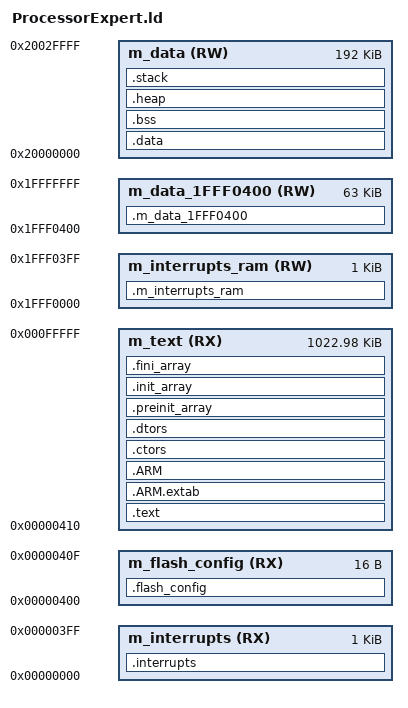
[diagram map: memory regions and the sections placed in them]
/*## ####################################################################### */
/*##                                                                         */
/*##     THIS COMPONENT MODULE IS GENERATED BY THE PROCESSOR EXPERT. DO NOT MODIFY IT. */
/*##                                                                         */
/*##     Filename  : ProcessorExpert.ld                                      */
/*##                                                                         */
/*##     Project   : FRDM-K64F_SDK_FreeRTOS_PEx                              */
/*##                                                                         */
/*##     Processor : MK64FN1M0VLQ12                                          */
/*##                                                                         */
/*##     Compiler  : GNU C Compiler                                          */
/*##                                                                         */
/*##     Date/Time : 2014-10-20, 20:41, # CodeGen: 0                         */
/*##                                                                         */
/*##     Abstract  :                                                         */
/*##                                                                         */
/*##     This file is used by the linker. It describes files to be linked,   */
/*##     memory ranges, stack size, etc. For detailed description about      */
/*##     linker command files see compiler documentation. This file is generated by default. */
/*##     You can switch off generation by setting the property "Generate linker file = no" */
/*##     in the "Build options" tab of the CPU component and then modify this file as needed. */
/*##                                                                         */
/*##                                                                         */
/*## ####################################################################### */
/* Entry Point */
ENTRY(Reset_Handler)

HEAP_SIZE  = DEFINED(__heap_size__)  ? __heap_size__  : 0x0400;
STACK_SIZE = DEFINED(__stack_size__) ? __stack_size__ : 0x0400;
M_VECTOR_RAM_SIZE = DEFINED(__ram_vector_table__) ? 0x0400 : 0x0;
/* Specify the memory areas */
MEMORY {
  m_interrupts          (RX)  : ORIGIN = 0x00000000, LENGTH = 0x00000400
  m_text                (RX)  : ORIGIN = 0x00000410, LENGTH = 0x000FFBF0
  m_interrupts_ram      (RW)  : ORIGIN = 0x1FFF0000, LENGTH = 0x00000400
  m_data_1FFF0400       (RW)  : ORIGIN = 0x1FFF0400, LENGTH = 0x0000FC00
  m_data                (RW)  : ORIGIN = 0x20000000, LENGTH = 0x00030000
  m_flash_config        (RX)  : ORIGIN = 0x00000400, LENGTH = 0x00000010
}

/* Define output sections */
SECTIONS
{
  /* The startup code goes first into INTERNAL_FLASH */
  .interrupts :
  {
    __VECTOR_TABLE = .;
    . = ALIGN(4);
    KEEP(*(.isr_vector))     /* Startup code */
    . = ALIGN(4);
  } > m_interrupts

  __VECTOR_RAM = ORIGIN(m_interrupts_ram);

  .flash_config :
  {
    . = ALIGN(4);
    KEEP(*(.FlashConfig))    /* Flash Configuration Field (FCF) */
    . = ALIGN(4);
  } > m_flash_config

  /* The program code and other data goes into INTERNAL_FLASH */
  .text :
  {
    . = ALIGN(4);
    *(.text)                 /* .text sections (code) */
    *(.text*)                /* .text* sections (code) */
    *(.rodata)               /* .rodata sections (constants, strings, etc.) */
    *(.rodata*)              /* .rodata* sections (constants, strings, etc.) */
    *(.glue_7)               /* glue arm to thumb code */
    *(.glue_7t)              /* glue thumb to arm code */
    *(.eh_frame)
    KEEP (*(.init))
    KEEP (*(.fini))
    . = ALIGN(4);
  } > m_text

  .ARM.extab :
  {
    *(.ARM.extab* .gnu.linkonce.armextab.*)
  } > m_text

  .ARM :
  {
    __exidx_start = .;
    *(.ARM.exidx*)
    __exidx_end = .;
  } > m_text

 .ctors :
  {
    __CTOR_LIST__ = .;
    /* gcc uses crtbegin.o to find the start of
       the constructors, so we make sure it is
       first.  Because this is a wildcard, it
       doesn't matter if the user does not
       actually link against crtbegin.o; the
       linker won't look for a file to match a
       wildcard.  The wildcard also means that it
       doesn't matter which directory crtbegin.o
       is in.  */
    KEEP (*crtbegin.o(.ctors))
    KEEP (*crtbegin?.o(.ctors))
    /* We don't want to include the .ctor section from
       from the crtend.o file until after the sorted ctors.
       The .ctor section from the crtend file contains the
       end of ctors marker and it must be last */
    KEEP (*(EXCLUDE_FILE(*crtend?.o *crtend.o) .ctors))
    KEEP (*(SORT(.ctors.*)))
    KEEP (*(.ctors))
    __CTOR_END__ = .;
  } > m_text

  .dtors :
  {
    __DTOR_LIST__ = .;
    KEEP (*crtbegin.o(.dtors))
    KEEP (*crtbegin?.o(.dtors))
    KEEP (*(EXCLUDE_FILE(*crtend?.o *crtend.o) .dtors))
    KEEP (*(SORT(.dtors.*)))
    KEEP (*(.dtors))
    __DTOR_END__ = .;
  } > m_text

  .preinit_array :
  {
    PROVIDE_HIDDEN (__preinit_array_start = .);
    KEEP (*(.preinit_array*))
    PROVIDE_HIDDEN (__preinit_array_end = .);
  } > m_text

  .init_array :
  {
    PROVIDE_HIDDEN (__init_array_start = .);
    KEEP (*(SORT(.init_array.*)))
    KEEP (*(.init_array*))
    PROVIDE_HIDDEN (__init_array_end = .);
  } > m_text

  .fini_array :
  {
    PROVIDE_HIDDEN (__fini_array_start = .);
    KEEP (*(SORT(.fini_array.*)))
    KEEP (*(.fini_array*))
    PROVIDE_HIDDEN (__fini_array_end = .);
  } > m_text
 
  __etext = .;    /* define a global symbol at end of code */
  __DATA_ROM = .; /* Symbol is used by startup for data initialization */

  .data : AT(__DATA_ROM)
  {
    . = ALIGN(4);
    __DATA_RAM = .;
    __data_start__ = .;      /* create a global symbol at data start */
    *(.data)                 /* .data sections */
    *(.data*)                /* .data* sections */
    KEEP(*(.jcr*))
    . = ALIGN(4);
    __data_end__ = .;        /* define a global symbol at data end */
  } > m_data

  /* Symbol is used by startup for data initialization */
  __DATA_END = __DATA_ROM + (__data_end__ - __data_start__);

  __m_interrupts_ram_ROMStart = __DATA_ROM + SIZEOF(.data);
  .m_interrupts_ram : AT(__m_interrupts_ram_ROMStart)
  {
     . = ALIGN(4);
     __m_interrupts_ram_RAMStart = .;
     *(.m_interrupts_ram)    /* This is an User defined section */
     __m_interrupts_ram_RAMEnd = .;
     . = ALIGN(4);
  } > m_interrupts_ram
  __m_interrupts_ram_ROMSize = __m_interrupts_ram_RAMEnd - __m_interrupts_ram_RAMStart;

  __m_data_1FFF0400_ROMStart = __m_interrupts_ram_ROMStart + SIZEOF(.m_interrupts_ram);
  .m_data_1FFF0400 : AT(__m_data_1FFF0400_ROMStart)
  {
     . = ALIGN(4);
     __m_data_1FFF0400_RAMStart = .;
     *(.m_data_1FFF0400)     /* This is an User defined section */
     __m_data_1FFF0400_RAMEnd = .;
     . = ALIGN(4);
  } > m_data_1FFF0400
  __m_data_1FFF0400_ROMSize = __m_data_1FFF0400_RAMEnd - __m_data_1FFF0400_RAMStart;

  /* Uninitialized data section */
  .bss :
  {
    /* This is used by the startup in order to initialize the .bss section */
    . = ALIGN(4);
    __START_BSS = .;
    __bss_start__ = .;
    *(.bss)
    *(.bss*)
    *(COMMON)
    . = ALIGN(4);
    __bss_end__ = .;
    __END_BSS = .;
  } > m_data

  .heap :
  {
    . = ALIGN(8);
    __end__ = .;
    PROVIDE(end = .);
    __HeapBase = .;
    . += HEAP_SIZE;
    __HeapLimit = .;
  } > m_data

  .stack :
  {
    . = ALIGN(8);
    . += STACK_SIZE;
  } > m_data

  __StackTop   = .;
  __StackLimit = __StackTop - STACK_SIZE;
  PROVIDE(__stack = __StackTop);

  .ARM.attributes 0 : { *(.ARM.attributes) }
}
